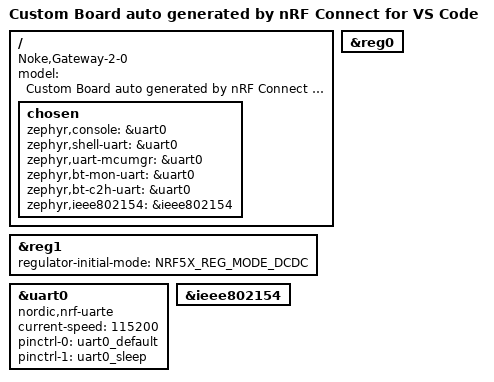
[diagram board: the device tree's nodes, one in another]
/dts-v1/;
#include <nordic/nrf52840_qiaa.dtsi>
#include "Gateway_2_0-pinctrl.dtsi"
#include <nordic/nrf52840_partition.dtsi>

/ {
	model = "Custom Board auto generated by nRF Connect for VS Code";
	compatible = "Noke,Gateway-2-0";

	chosen {
		zephyr,console = &uart0;
		zephyr,shell-uart = &uart0;
		zephyr,uart-mcumgr = &uart0;
		zephyr,bt-mon-uart = &uart0;
		zephyr,bt-c2h-uart = &uart0;
		zephyr,ieee802154 = &ieee802154;
	};
};

&reg0 {
	status = "okay";
};

&reg1 {
	regulator-initial-mode = <NRF5X_REG_MODE_DCDC>;
};

&uart0 {
	compatible = "nordic,nrf-uarte";
	status = "okay";
	current-speed = <115200>;
	pinctrl-0 = <&uart0_default>;
	pinctrl-1 = <&uart0_sleep>;
	pinctrl-names = "default", "sleep";
};

&ieee802154 {
	status = "okay";
};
